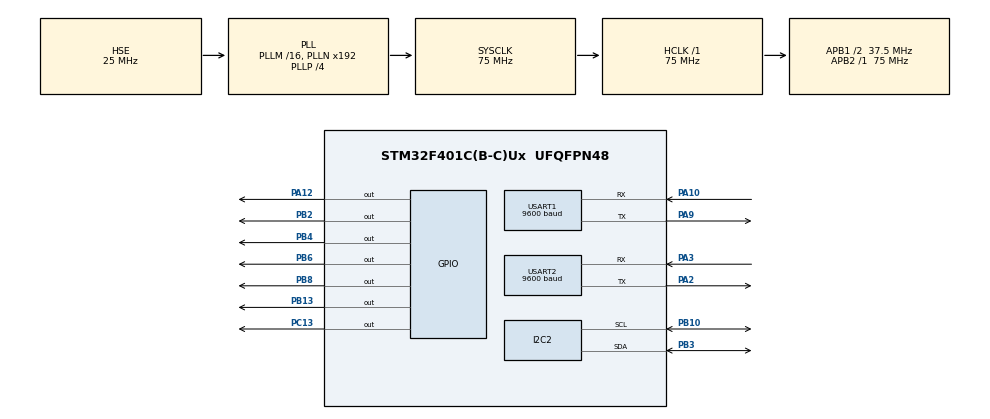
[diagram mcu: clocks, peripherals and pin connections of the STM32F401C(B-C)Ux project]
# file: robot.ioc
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Mcu.Family=STM32F4
Mcu.Name=STM32F401C(B-C)Ux
Mcu.Package=UFQFPN48
NVIC.PriorityGroup=NVIC_PRIORITYGROUP_4
NVIC.TIM1_UP_TIM10_IRQn=true\:0\:0\:false\:false\:true\:true\:true
NVIC.USART1_IRQn=true\:0\:0\:false\:false\:true\:true\:true
NVIC.USART2_IRQn=true\:0\:0\:false\:false\:true\:true\:true
PA10.Mode=Asynchronous
PA10.Signal=USART1_RX
PA12.Signal=GPIO_Output
PA13.Mode=Serial_Wire
PA13.Signal=SYS_JTMS-SWDIO
PA14.Mode=Serial_Wire
PA14.Signal=SYS_JTCK-SWCLK
PA2.Mode=Asynchronous
PA2.Signal=USART2_TX
PA3.Mode=Asynchronous
PA3.Signal=USART2_RX
PA9.Mode=Asynchronous
PA9.Signal=USART1_TX
PB10.Mode=I2C
PB10.Signal=I2C2_SCL
PB13.Signal=GPIO_Output
PB2.Signal=GPIO_Output
PB3.Mode=I2C
PB3.Signal=I2C2_SDA
PB4.Signal=GPIO_Output
PB6.Signal=GPIO_Output
PB8.Signal=GPIO_Output
PC13-ANTI_TAMP.Signal=GPIO_Output
PH0\ -\ OSC_IN.Mode=HSE-External-Oscillator
PH0\ -\ OSC_IN.Signal=RCC_OSC_IN
PH1\ -\ OSC_OUT.Mode=HSE-External-Oscillator
PH1\ -\ OSC_OUT.Signal=RCC_OSC_OUT
ProjectManager.HeapSize=0x200
ProjectManager.StackSize=0x400
ProjectManager.TargetToolchain=MDK-ARM V5.32
RCC.48MHZClocksFreq_Value=75000000
RCC.AHBFreq_Value=75000000
RCC.APB1CLKDivider=RCC_HCLK_DIV2
RCC.APB1Freq_Value=37500000
RCC.APB1TimFreq_Value=75000000
RCC.APB2Freq_Value=75000000
RCC.APB2TimFreq_Value=75000000
RCC.CortexFreq_Value=75000000
RCC.HCLKFreq_Value=75000000
RCC.HSE_VALUE=25000000
RCC.HSI_VALUE=16000000
RCC.LSE_VALUE=32768
RCC.PLLP=RCC_PLLP_DIV4
RCC.PLLSourceVirtual=RCC_PLLSOURCE_HSE
RCC.SYSCLKFreq_VALUE=75000000
RCC.SYSCLKSource=RCC_SYSCLKSOURCE_PLLCLK
RCC.VCOOutputFreq_Value=300000000
TIM1.Period=1000-1
TIM1.Prescaler=75-1
TIM11.Period=0xffff-1
TIM11.Prescaler=75-1
USART1.BaudRate=9600
USART1.VirtualMode=VM_ASYNC
USART2.BaudRate=9600
USART2.VirtualMode=VM_ASYNC
VP_TIM11_VS_ClockSourceINT.Mode=Enable_Timer
VP_TIM1_VS_ClockSourceINT.Mode=Internal
board=custom

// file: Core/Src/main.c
/* USER CODE BEGIN Header */
/**
  ******************************************************************************
  * @file           : main.c
  * @brief          : Main program body
  ******************************************************************************
  * @attention
  *
  * <h2><center>&copy; Copyright (c) 2023 STMicroelectronics.
  * All rights reserved.</center></h2>
  *
  * This software component is licensed by ST under BSD 3-Clause license,
  * the "License"; You may not use this file except in compliance with the
  * License. You may obtain a copy of the License at:
  *                        opensource.org/licenses/BSD-3-Clause
  *
  ******************************************************************************
  */
/* USER CODE END Header */
#include "main.h"
#include "i2c.h"
#include "tim.h"
#include "usart.h"
#include "gpio.h"

/* USER CODE BEGIN Includes */
#include "delay.h"
#include "print.h"
#include "oled.h"
/* USER CODE END Includes */

/* USER CODE BEGIN PV */
extern uint8_t receive_byte;

extern uint16_t action_counter;
extern uint8_t action_select;
/* USER CODE END PV */

void SystemClock_Config(void);

int main(void)
{

  /* MCU Configuration--------------------------------------------------------*/

  /* Reset of all peripherals, Initializes the Flash interface and the Systick. */
  HAL_Init();

  /* Configure the system clock */
  SystemClock_Config();

  /* Initialize all configured peripherals */
  MX_GPIO_Init();
  MX_TIM11_Init();
  MX_TIM1_Init();
  MX_USART1_UART_Init();
  MX_USART2_UART_Init();
  MX_I2C2_Init();
  /* USER CODE BEGIN 2 */
  HAL_TIM_Base_Start_IT(&htim1);
  HAL_TIM_Base_Start(&htim11);

  HAL_UART_Receive_IT(&huart1, &receive_byte, 1);
  /* USER CODE END 2 */

  /* Infinite loop */
  /* USER CODE BEGIN WHILE */
  OLED_Init();
  while (1)
  {
    /* USER CODE END WHILE */

    /* USER CODE BEGIN 3 */

//    HAL_GPIO_TogglePin(GPIOC, GPIO_PIN_13);
//    delay_ms(999);

    // this works
    // usart_printf(&huart2, "%c", receive_byte);

    OLED_Clear();
    OLED_printf(0, 0, "action_select=%d", action_select);
    OLED_Refresh_Gram();

    HAL_Delay(100);
  }
  /* USER CODE END 3 */
}

void SystemClock_Config(void)
{
  RCC_OscInitTypeDef RCC_OscInitStruct = {0};
  RCC_ClkInitTypeDef RCC_ClkInitStruct = {0};

  /** Configure the main internal regulator output voltage
  */
  __HAL_RCC_PWR_CLK_ENABLE();
  __HAL_PWR_VOLTAGESCALING_CONFIG(PWR_REGULATOR_VOLTAGE_SCALE2);
  /** Initializes the RCC Oscillators according to the specified parameters
  * in the RCC_OscInitTypeDef structure.
  */
  RCC_OscInitStruct.OscillatorType = RCC_OSCILLATORTYPE_HSE;
  RCC_OscInitStruct.HSEState = RCC_HSE_ON;
  RCC_OscInitStruct.PLL.PLLState = RCC_PLL_ON;
  RCC_OscInitStruct.PLL.PLLSource = RCC_PLLSOURCE_HSE;
  RCC_OscInitStruct.PLL.PLLM = 16;
  RCC_OscInitStruct.PLL.PLLN = 192;
  RCC_OscInitStruct.PLL.PLLP = RCC_PLLP_DIV4;
  RCC_OscInitStruct.PLL.PLLQ = 4;
  if (HAL_RCC_OscConfig(&RCC_OscInitStruct) != HAL_OK)
  {
    Error_Handler();
  }
  /** Initializes the CPU, AHB and APB buses clocks
  */
  RCC_ClkInitStruct.ClockType = RCC_CLOCKTYPE_HCLK|RCC_CLOCKTYPE_SYSCLK
                              |RCC_CLOCKTYPE_PCLK1|RCC_CLOCKTYPE_PCLK2;
  RCC_ClkInitStruct.SYSCLKSource = RCC_SYSCLKSOURCE_PLLCLK;
  RCC_ClkInitStruct.AHBCLKDivider = RCC_SYSCLK_DIV1;
  RCC_ClkInitStruct.APB1CLKDivider = RCC_HCLK_DIV2;
  RCC_ClkInitStruct.APB2CLKDivider = RCC_HCLK_DIV1;

  if (HAL_RCC_ClockConfig(&RCC_ClkInitStruct, FLASH_LATENCY_2) != HAL_OK)
  {
    Error_Handler();
  }
}

void Error_Handler(void)
{
  __disable_irq();
  while (1)
  {
  }
}

/************************ (C) COPYRIGHT STMicroelectronics *****END OF FILE****/
